# PIC32MM0064GPM036 register map
Vendor: Microchip
Registers are 32-bit, read-write, reset 0x0 unless marked. A register's access mark holds for its fields unless they carry their own. Addresses are absolute, and some are shared; only a register's first bit layout is shown; [hi:lo] are bit positions; {n}, {i} and the like mark numbered series.

## SPI2
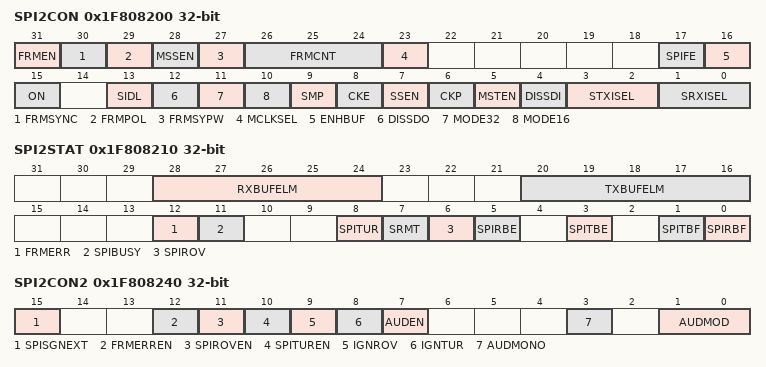
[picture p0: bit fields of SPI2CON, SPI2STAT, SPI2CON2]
0x1F808200 SPI2CON reset not defined — (power-on value 00000000x-----0000000000000x0000)
  [31] FRMEN, [30] FRMSYNC, [29] FRMPOL, [28] MSSEN, [27] FRMSYPW, [26:24] FRMCNT, [23] MCLKSEL, [17] SPIFE, [16] ENHBUF, [15] ON, [13] SIDL, [12] DISSDO, [11] MODE32, [10] MODE16, [9] SMP, [8] CKE, [7] SSEN, [6] CKP, [5] MSTEN, [4] DISSDI, [3:2] STXISEL, [1:0] SRXISEL
0x1F808210 SPI2STAT reset not defined — (power-on value ---00000---00000---x0--0000-0-00)
  [28:24] RXBUFELM ro, [20:16] TXBUFELM ro, [12] FRMERR, [11] SPIBUSY ro, [8] SPITUR ro, [7] SRMT ro, [6] SPIROV ro, [5] SPIRBE ro, [3] SPITBE ro, [1] SPITBF ro, [0] SPIRBF ro
0x1F808220 SPI2BUF reset not defined — (power-on value xxxxxxxxxxxxxxxxxxxxxxxxxxxxxxxx)
0x1F808230 SPI2BRG reset not defined — (power-on value -------------------xxxxxxxxxxxxx)
  [12:0] SPI2BRG
0x1F808240 SPI2CON2 reset not defined — (power-on value ----------------x--xxxxxx---x-xx)
  [15] SPISGNEXT, [12] FRMERREN, [11] SPIROVEN, [10] SPITUREN, [9] IGNROV, [8] IGNTUR, [7] AUDEN, [3] AUDMONO, [1:0] AUDMOD

## SPI3
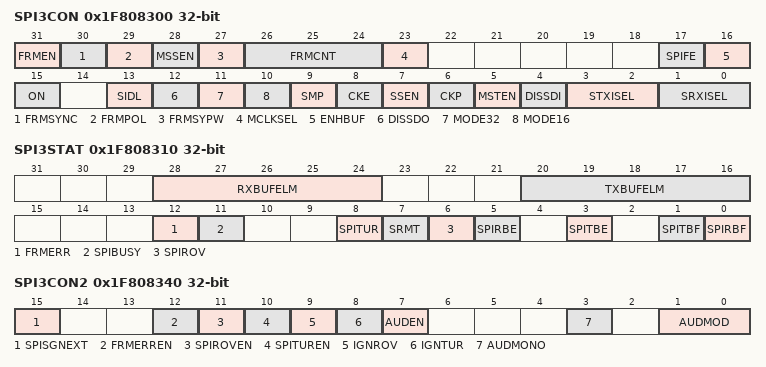
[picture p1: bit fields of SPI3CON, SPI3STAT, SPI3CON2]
0x1F808300 SPI3CON reset not defined — (power-on value 00000000x-----0000000000000x0000)
  [31] FRMEN, [30] FRMSYNC, [29] FRMPOL, [28] MSSEN, [27] FRMSYPW, [26:24] FRMCNT, [23] MCLKSEL, [17] SPIFE, [16] ENHBUF, [15] ON, [13] SIDL, [12] DISSDO, [11] MODE32, [10] MODE16, [9] SMP, [8] CKE, [7] SSEN, [6] CKP, [5] MSTEN, [4] DISSDI, [3:2] STXISEL, [1:0] SRXISEL
0x1F808310 SPI3STAT reset not defined — (power-on value ---00000---00000---x0--0000-0-00)
  [28:24] RXBUFELM ro, [20:16] TXBUFELM ro, [12] FRMERR, [11] SPIBUSY ro, [8] SPITUR ro, [7] SRMT ro, [6] SPIROV ro, [5] SPIRBE ro, [3] SPITBE ro, [1] SPITBF ro, [0] SPIRBF ro
0x1F808320 SPI3BUF reset not defined — (power-on value xxxxxxxxxxxxxxxxxxxxxxxxxxxxxxxx)
0x1F808330 SPI3BRG reset not defined — (power-on value -------------------xxxxxxxxxxxxx)
  [12:0] SPI3BRG
0x1F808340 SPI3CON2 reset not defined — (power-on value ----------------x--xxxxxx---x-xx)
  [15] SPISGNEXT, [12] FRMERREN, [11] SPIROVEN, [10] SPITUREN, [9] IGNROV, [8] IGNTUR, [7] AUDEN, [3] AUDMONO, [1:0] AUDMOD

## USB1
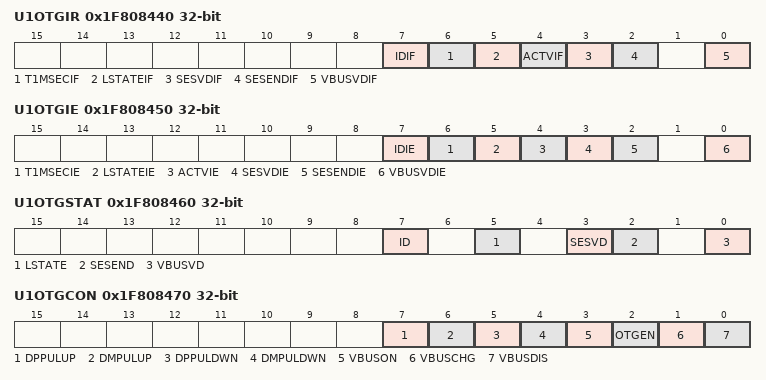
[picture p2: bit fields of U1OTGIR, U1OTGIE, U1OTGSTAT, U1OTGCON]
0x1F808440 U1OTGIR
  [7] IDIF, [6] T1MSECIF, [5] LSTATEIF, [4] ACTVIF, [3] SESVDIF, [2] SESENDIF, [0] VBUSVDIF
0x1F808450 U1OTGIE
  [7] IDIE, [6] T1MSECIE, [5] LSTATEIE, [4] ACTVIE, [3] SESVDIE, [2] SESENDIE, [0] VBUSVDIE
0x1F808460 U1OTGSTAT
  [7] ID, [5] LSTATE, [3] SESVD, [2] SESEND, [0] VBUSVD
0x1F808470 U1OTGCON
  [7] DPPULUP, [6] DMPULUP, [5] DPPULDWN, [4] DMPULDWN, [3] VBUSON, [2] OTGEN, [1] VBUSCHG, [0] VBUSDIS
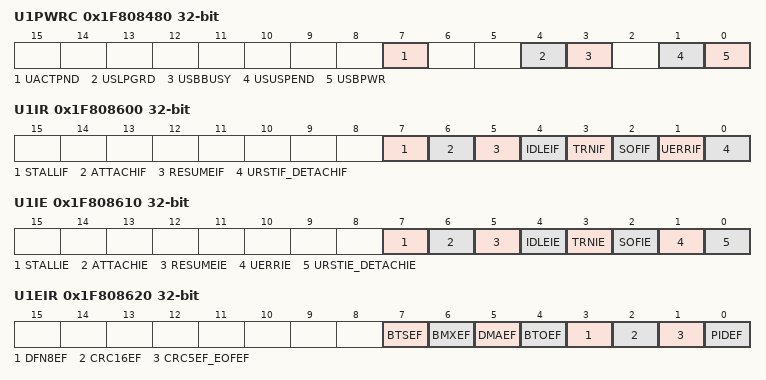
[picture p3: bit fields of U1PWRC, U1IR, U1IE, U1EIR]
0x1F808480 U1PWRC reset not defined — (power-on value ------------------------0--0x-00)
  [7] UACTPND ro, [4] USLPGRD, [3] USBBUSY, [1] USUSPEND, [0] USBPWR
0x1F808600 U1IR
  [7] STALLIF, [6] ATTACHIF, [5] RESUMEIF, [4] IDLEIF, [3] TRNIF, [2] SOFIF, [1] UERRIF, [0] URSTIF_DETACHIF
0x1F808610 U1IE
  [7] STALLIE, [6] ATTACHIE, [5] RESUMEIE, [4] IDLEIE, [3] TRNIE, [2] SOFIE, [1] UERRIE, [0] URSTIE_DETACHIE
0x1F808620 U1EIR
  [7] BTSEF, [6] BMXEF, [5] DMAEF, [4] BTOEF, [3] DFN8EF, [2] CRC16EF, [1] CRC5EF_EOFEF, [0] PIDEF
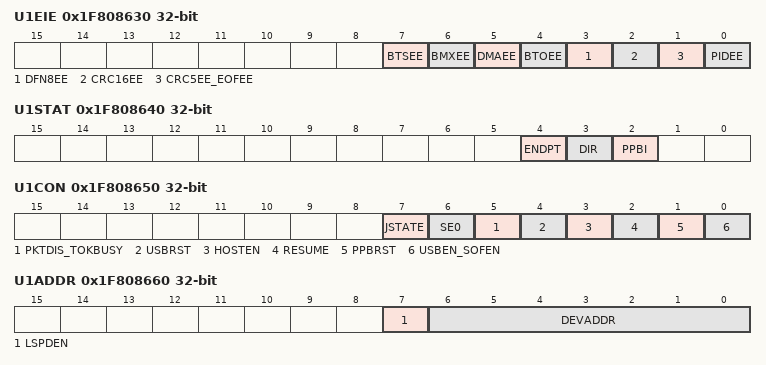
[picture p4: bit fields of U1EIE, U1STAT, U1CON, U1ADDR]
0x1F808630 U1EIE reset not defined — (power-on value ------------------------0000000x)
  [7] BTSEE, [6] BMXEE, [5] DMAEE, [4] BTOEE, [3] DFN8EE, [2] CRC16EE, [1] CRC5EE_EOFEE, [0] PIDEE
0x1F808640 U1STAT ro reset not defined
  [4] ENDPT, [3] DIR, [2] PPBI
0x1F808650 U1CON
  [7] JSTATE, [6] SE0, [5] PKTDIS_TOKBUSY, [4] USBRST, [3] HOSTEN, [2] RESUME, [1] PPBRST, [0] USBEN_SOFEN
0x1F808660 U1ADDR
  [7] LSPDEN, [6:0] DEVADDR
0x1F808670 U1BDTP1
  [7:1] BDTPTRL
0x1F808680 U1FRML ro reset not defined
  [7:0] FRML
0x1F808690 U1FRMH ro reset not defined
  [2:0] FRMH
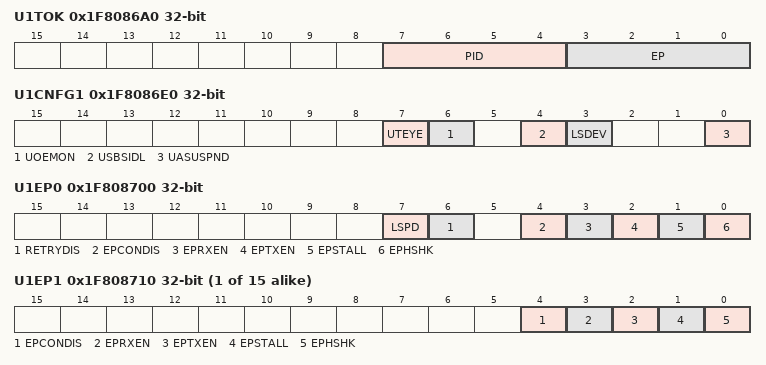
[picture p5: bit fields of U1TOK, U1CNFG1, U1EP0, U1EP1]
0x1F8086A0 U1TOK
  [7:4] PID, [3:0] EP
0x1F8086B0 U1SOF
  [7:0] CNT
0x1F8086C0 U1BDTP2
  [7:0] BDTPTRH
0x1F8086D0 U1BDTP3
  [7:0] BDTPTRU
0x1F8086E0 U1CNFG1 reset not defined — (power-on value ------------------------xxxxx00x)
  [7] UTEYE, [6] UOEMON, [4] USBSIDL, [3] LSDEV, [0] UASUSPND
0x1F808700 U1EP0
  [7] LSPD, [6] RETRYDIS, [4] EPCONDIS, [3] EPRXEN, [2] EPTXEN, [1] EPSTALL, [0] EPHSHK
{0x1F808700+0x10*i} U1EP{i} (i=1..15)
  [4] EPCONDIS, [3] EPRXEN, [2] EPTXEN, [1] EPSTALL, [0] EPHSHK
